# V8M_Generic register map
Vendor: ARM Ltd.; Series: M; File version: 2020-08-22T15:13:24.354567-05:00
CPU: CM4 r0p0, little endian, vendor SysTick, 8 interrupt priority bits
Registers are 32-bit, read-write, no defined reset value unless marked. A register's access mark holds for its fields unless they carry their own. Offsets are from the block's base; [hi:lo] are bit positions; lines under a group give offsets from that group; {n}, {i} and the like mark numbered series; 'fields as' and 'values as' point back to an identical list.

## NVIC — Nested Vectored Interrupt Controller
Base 0xE000E100
0x00 NVIC_ISER{i} (i=0..15) — Enables or reads the enabled state of each group of 32 interrupts
  [31:0] SETENA — Set enable
    0=No_effect; 1=Enable_interrupt_{32i}_m
0x128 NVIC_ICER{i} (i=0..15) — Clears or reads the enabled state of each group of 32 interrupts
  [31:0] CLRENA — Clear enable
    0=No_effect; 1=Disable_interrupt_{32i}_m
0x256 NVIC_ISPR{i} (i=0..15) — Enables or reads the pending state of each group of 32 interrupts
  [31:0] SETPEND — Set pending
    0=No_effect; 1=Pend_interrupt_{32i}_m
0x384 NVIC_ICPR{i} (i=0..15) — Clears or reads the pending state of each group of 32 interrupts
  [31:0] CLRPEND — Clear pending
    0=No_effect; 1=Clear_pending_state_of_interrupt_{32i}_m
0x512 NVIC_IABR{i} ro (i=0..15) — For each group of 32 interrupts, shows the active state of each interrupt
  [31:0] ACTIVE — Active state
    0=Interrupt_not_active; 1=Interrupt_is_active
0x640 NVIC_ITNS{i} (i=0..15) — For each group of 32 interrupts, determines whether each interrupt targets Non-secure or Secure state
  [31:0] ITNS — Interrupt Targets Non-secure
    0=Interrupt_targets_Secure_state; 1=Interrupt_targets_Non_secure_state
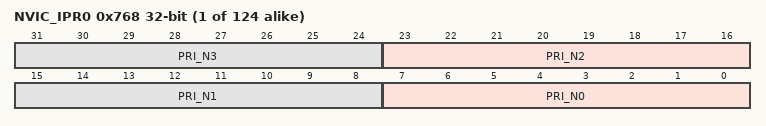
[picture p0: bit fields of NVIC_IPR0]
0x768 NVIC_IPR{i} (i=0..123) — Sets or reads interrupt priorities
  [8n+7:8n] PRI_N{n} (n=0..3) — Priority '{4i}'+{n}

## SIG — Software Interrupt Control
Base 0xE000EF00
0x00 STIR wo — Provides a mechanism for software to generate an interrupt
  [8:0] INTID — Interrupt ID

## SYST — SysTick Control Registers
Base 0xE000E010
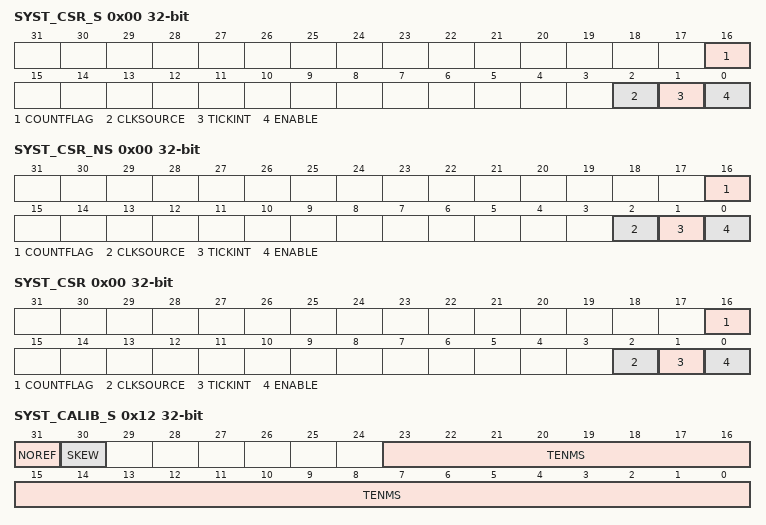
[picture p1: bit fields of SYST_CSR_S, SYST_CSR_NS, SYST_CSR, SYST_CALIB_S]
0x00 SYST_CSR_S — Controls the SysTick timer and provides status data FTSSS
  [16] COUNTFLAG
    0=Timer_has_not_counted_to_0; 1=Timer_has_counted_to_0
  [2] CLKSOURCE — Clock source
    0=Uses_the_IMPLEMENTATION_DEFINED_external_reference_clock; 1=Uses_the_PE_clock
  [1] TICKINT — Tick interrupt
    0=Count_to_0_does_not_affect_the_SysTick_exception_status; 1=Count_to_0_changes_the_SysTick_exception_status_to_pending
  [0] ENABLE — SysTick enable
    0=Counter_is_disabled; 1=Counter_is_enabled
0x00 SYST_CSR_NS — Controls the SysTick timer and provides status data FTSSS
  fields as SYST_CSR_S
0x00 SYST_CSR — Controls the SysTick timer and provides status data FTSSS
  fields as SYST_CSR_S
0x04 SYST_RVR_S — Provides access SysTick timer counter reload value FTSSS
  [23:0] RELOAD — Counter reload value
0x04 SYST_RVR_NS — Provides access SysTick timer counter reload value FTSSS
  [23:0] RELOAD — Counter reload value
0x04 SYST_RVR — Provides access SysTick timer counter reload value FTSSS
  [23:0] RELOAD — Counter reload value
0x08 SYST_CVR_S — Reads or clears the SysTick timer current counter value FTSSS
  [23:0] CURRENT — Current counter value
0x08 SYST_CVR_NS — Reads or clears the SysTick timer current counter value FTSSS
  [23:0] CURRENT — Current counter value
0x08 SYST_CVR — Reads or clears the SysTick timer current counter value FTSSS
  [23:0] CURRENT — Current counter value
0x12 SYST_CALIB_S ro — Reads the SysTick timer calibration value and parameters FTSSS
  [31] NOREF — No reference
    0=Reference_clock_is_implemented; 1=Reference_clock_is_not_implemented
  [30] SKEW
    0=TENMS_calibration_value_is_exact; 1=TENMS_calibration_value_is_inexact
  [23:0] TENMS — Ten milliseconds
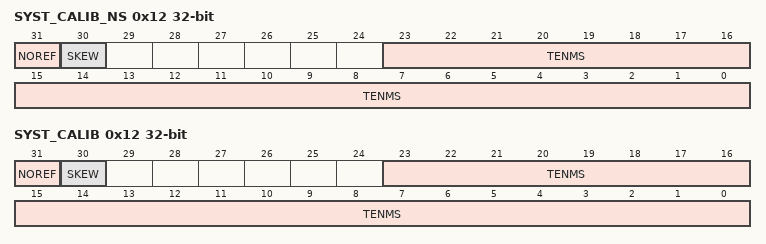
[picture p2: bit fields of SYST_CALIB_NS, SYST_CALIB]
0x12 SYST_CALIB_NS ro — Reads the SysTick timer calibration value and parameters FTSSS
  fields as SYST_CALIB_S
0x12 SYST_CALIB ro — Reads the SysTick timer calibration value and parameters FTSSS
  fields as SYST_CALIB_S

## SAU — Security Attribute Unit
Base 0xE000EDD0
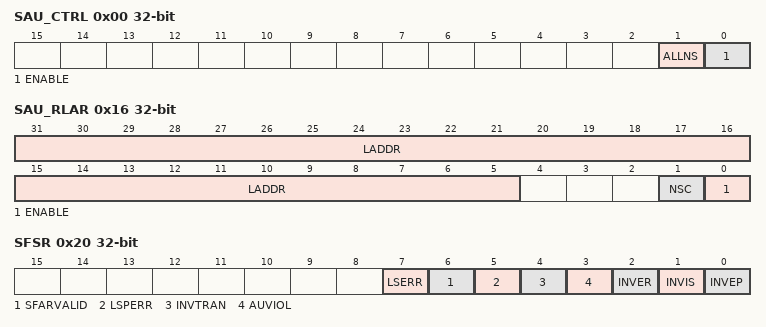
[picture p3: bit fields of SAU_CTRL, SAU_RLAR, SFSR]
0x00 SAU_CTRL — Allows enabling of the Security Attribution Unit
  [1] ALLNS — All Non-secure
    0=Memory_is_marked_as_Secure_and_is_not_Non_secure_callable; 1=Memory_is_marked_as_Non_secure
  [0] ENABLE
    0=The_SAU_is_disabled; 1=The_SAU_is_enabled
0x04 SAU_TYPE ro — Indicates the number of regions implemented by the Security Attribution Unit
  [7:0] SREGION — SAU regions
0x08 SAU_RNR — Selects the region currently accessed by SAU_RBAR and SAU_RLAR
  [7:0] REGION — Region number
0x12 SAU_RBAR — Provides indirect read and write access to the base address of the currently selected SAU region
  [31:5] BADDR — Base address
0x16 SAU_RLAR — Provides indirect read and write access to the limit address of the currently selected SAU region
  [31:5] LADDR — Limit address
  [1] NSC — Non-secure callable
    0=Region_is_not_Non_secure_callable; 1=Region_is_Non_secure_callable
  [0] ENABLE
    0=SAU_region_is_disabled; 1=SAU_region_is_enabled
0x20 SFSR — Provides information about any security related faults
  [7] LSERR — Lazy state error flag
    0=Error_has_not_occurred; 1=Error_has_occurred
  [6] SFARVALID — Secure fault address valid
    0=SFAR_content_not_valid; 1=SFAR_content_valid
  [5] LSPERR — Lazy state preservation error flag
    0=Error_has_not_occurred; 1=Error_has_occurred
  [4] INVTRAN — Invalid transition flag
    0=Error_has_not_occurred; 1=Error_has_occurred
  [3] AUVIOL — Attribution unit violation flag
    0=Error_has_not_occurred; 1=Error_has_occurred
  [2] INVER — Invalid exception return flag
    0=Error_has_not_occurred; 1=Error_has_occurred
  [1] INVIS — Invalid integrity signature flag
    0=Error_has_not_occurred; 1=Error_has_occurred
  [0] INVEP — Invalid entry point
    0=Error_has_not_occurred; 1=Error_has_occurred
0x24 SFAR — Shows the address of the memory location that caused a Security violation
  [31:0] ADDRESS
